# ESP8266 register map
File version: 1.0
CPU: Xtensa LX106 1, little endian, no MPU, no FPU, 3 interrupt priority bits
Registers are 32-bit, read-write, reset 0x0 unless marked. A register's access mark holds for its fields unless they carry their own. Offsets are from the block's base; [hi:lo] are bit positions; {n}, {i} and the like mark numbered series; 'fields as' and 'values as' point back to an identical list.

## I2S
Base 0x60000E00
0x00 I2STXFIFO
0x04 I2SRXFIFO
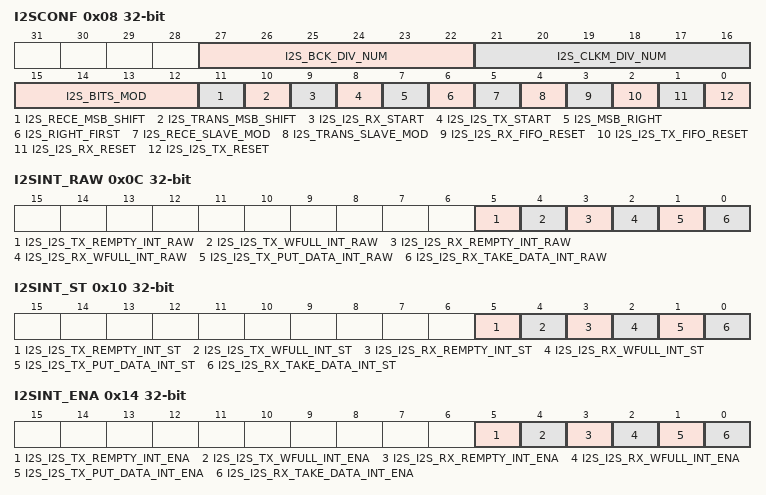
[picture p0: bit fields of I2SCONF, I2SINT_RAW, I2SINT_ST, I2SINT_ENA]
0x08 I2SCONF
  [27:22] I2S_BCK_DIV_NUM, [21:16] I2S_CLKM_DIV_NUM, [15:12] I2S_BITS_MOD, [11] I2S_RECE_MSB_SHIFT, [10] I2S_TRANS_MSB_SHIFT, [9] I2S_I2S_RX_START, [8] I2S_I2S_TX_START, [7] I2S_MSB_RIGHT, [6] I2S_RIGHT_FIRST, [5] I2S_RECE_SLAVE_MOD, [4] I2S_TRANS_SLAVE_MOD, [3] I2S_I2S_RX_FIFO_RESET, [2] I2S_I2S_TX_FIFO_RESET, [1] I2S_I2S_RX_RESET, [0] I2S_I2S_TX_RESET
0x0C I2SINT_RAW
  [5] I2S_I2S_TX_REMPTY_INT_RAW, [4] I2S_I2S_TX_WFULL_INT_RAW, [3] I2S_I2S_RX_REMPTY_INT_RAW, [2] I2S_I2S_RX_WFULL_INT_RAW, [1] I2S_I2S_TX_PUT_DATA_INT_RAW, [0] I2S_I2S_RX_TAKE_DATA_INT_RAW
0x10 I2SINT_ST
  [5] I2S_I2S_TX_REMPTY_INT_ST, [4] I2S_I2S_TX_WFULL_INT_ST, [3] I2S_I2S_RX_REMPTY_INT_ST, [2] I2S_I2S_RX_WFULL_INT_ST, [1] I2S_I2S_TX_PUT_DATA_INT_ST, [0] I2S_I2S_RX_TAKE_DATA_INT_ST
0x14 I2SINT_ENA
  [5] I2S_I2S_TX_REMPTY_INT_ENA, [4] I2S_I2S_TX_WFULL_INT_ENA, [3] I2S_I2S_RX_REMPTY_INT_ENA, [2] I2S_I2S_RX_WFULL_INT_ENA, [1] I2S_I2S_TX_PUT_DATA_INT_ENA, [0] I2S_I2S_RX_TAKE_DATA_INT_ENA
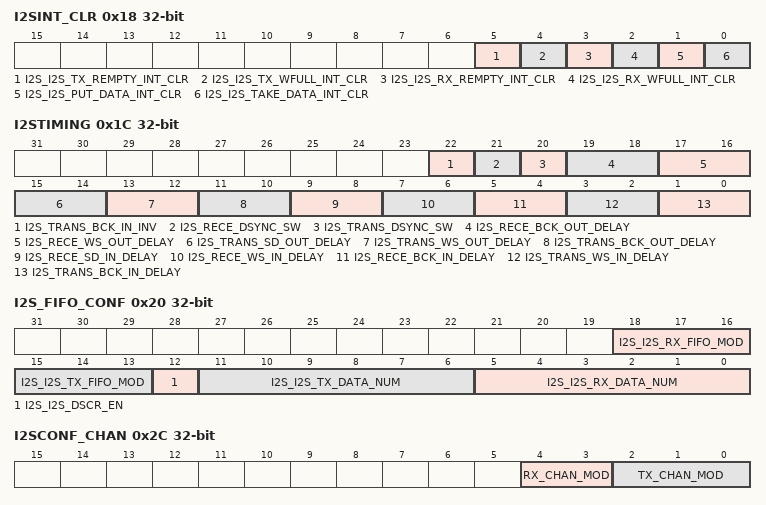
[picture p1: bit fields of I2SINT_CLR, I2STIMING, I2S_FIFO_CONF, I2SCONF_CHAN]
0x18 I2SINT_CLR
  [5] I2S_I2S_TX_REMPTY_INT_CLR, [4] I2S_I2S_TX_WFULL_INT_CLR, [3] I2S_I2S_RX_REMPTY_INT_CLR, [2] I2S_I2S_RX_WFULL_INT_CLR, [1] I2S_I2S_PUT_DATA_INT_CLR, [0] I2S_I2S_TAKE_DATA_INT_CLR
0x1C I2STIMING
  [22] I2S_TRANS_BCK_IN_INV, [21] I2S_RECE_DSYNC_SW, [20] I2S_TRANS_DSYNC_SW, [19:18] I2S_RECE_BCK_OUT_DELAY, [17:16] I2S_RECE_WS_OUT_DELAY, [15:14] I2S_TRANS_SD_OUT_DELAY, [13:12] I2S_TRANS_WS_OUT_DELAY, [11:10] I2S_TRANS_BCK_OUT_DELAY, [9:8] I2S_RECE_SD_IN_DELAY, [7:6] I2S_RECE_WS_IN_DELAY, [5:4] I2S_RECE_BCK_IN_DELAY, [3:2] I2S_TRANS_WS_IN_DELAY, [1:0] I2S_TRANS_BCK_IN_DELAY
0x20 I2S_FIFO_CONF
  [18:16] I2S_I2S_RX_FIFO_MOD, [15:13] I2S_I2S_TX_FIFO_MOD, [12] I2S_I2S_DSCR_EN, [11:6] I2S_I2S_TX_DATA_NUM, [5:0] I2S_I2S_RX_DATA_NUM
0x24 I2SRXEOF_NUM
  [31:0] I2S_I2S_RX_EOF_NUM
0x28 I2SCONF_SIGLE_DATA
  [31:0] I2S_I2S_SIGLE_DATA
0x2C I2SCONF_CHAN — I2S channel mode
  [4:3] RX_CHAN_MOD — Receive channel mode
  [2:0] TX_CHAN_MOD — Transmit channel mode

## IO_MUX
Base 0x60000800
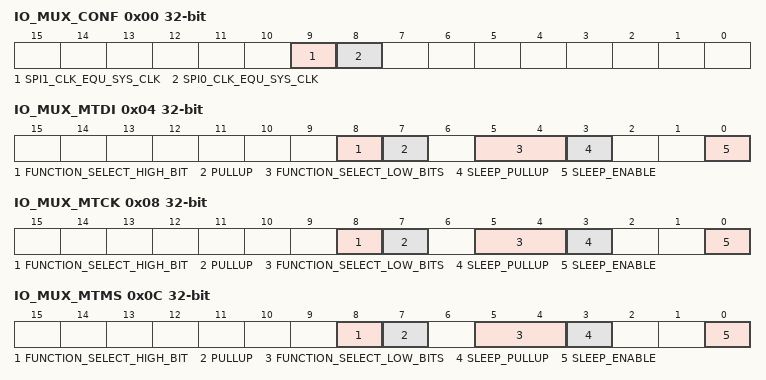
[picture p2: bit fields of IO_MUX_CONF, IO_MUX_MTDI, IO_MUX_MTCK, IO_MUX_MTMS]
0x00 IO_MUX_CONF
  [9] SPI1_CLK_EQU_SYS_CLK, [8] SPI0_CLK_EQU_SYS_CLK
0x04 IO_MUX_MTDI access not given
  [8] FUNCTION_SELECT_HIGH_BIT — configures IO_MUX function, upper bit
  [7] PULLUP — configures pull up
  [5:4] FUNCTION_SELECT_LOW_BITS — configures IO_MUX function, bottom 2 bits
  [3] SLEEP_PULLUP — configures pull up during sleep mode
  [0] SLEEP_ENABLE — configures output enable during sleep mode
0x08 IO_MUX_MTCK access not given
  fields as IO_MUX_MTDI
0x0C IO_MUX_MTMS access not given
  fields as IO_MUX_MTDI
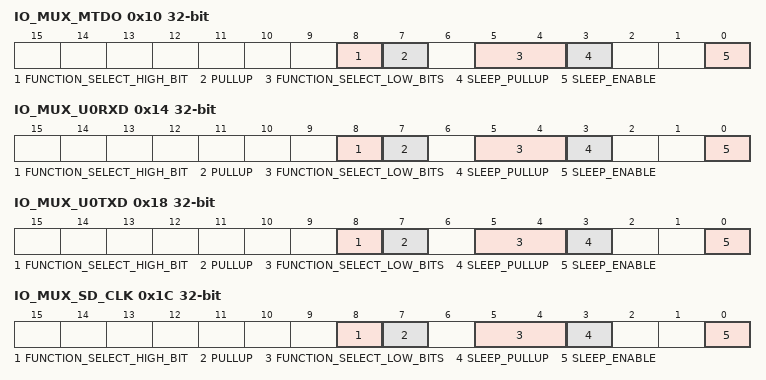
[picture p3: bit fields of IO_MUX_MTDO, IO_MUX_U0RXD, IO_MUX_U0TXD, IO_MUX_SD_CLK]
0x10 IO_MUX_MTDO access not given
  fields as IO_MUX_MTDI
0x14 IO_MUX_U0RXD access not given
  fields as IO_MUX_MTDI
0x18 IO_MUX_U0TXD access not given
  fields as IO_MUX_MTDI
0x1C IO_MUX_SD_CLK access not given
  fields as IO_MUX_MTDI
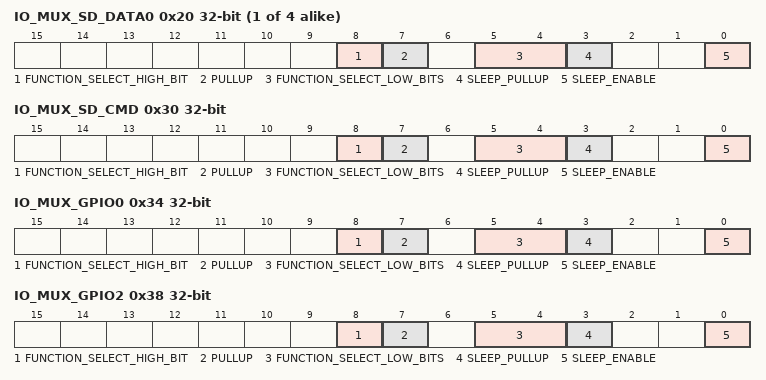
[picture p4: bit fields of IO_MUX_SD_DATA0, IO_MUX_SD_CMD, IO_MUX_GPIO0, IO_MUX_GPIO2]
{0x20+4i} IO_MUX_SD_DATA{i} access not given (i=0..3)
  fields as IO_MUX_MTDI
0x30 IO_MUX_SD_CMD access not given
  fields as IO_MUX_MTDI
0x34 IO_MUX_GPIO0 access not given
  fields as IO_MUX_MTDI
0x38 IO_MUX_GPIO2 access not given
  fields as IO_MUX_MTDI
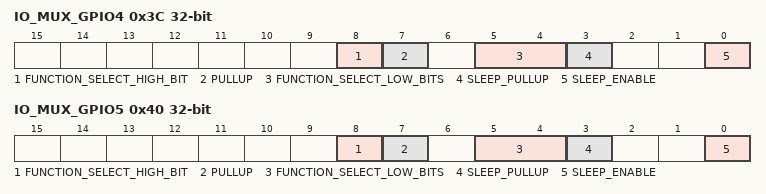
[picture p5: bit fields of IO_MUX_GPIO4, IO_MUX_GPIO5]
0x3C IO_MUX_GPIO4 access not given
  fields as IO_MUX_MTDI
0x40 IO_MUX_GPIO5 access not given
  fields as IO_MUX_MTDI

## RTC
Base 0x60000700
0x04 RTC_SLP_VAL — Target value of the RTC counter for waking from light or deep sleep
0x14 RTC_STATE1
0x18 RTC_STATE2
0x1C RTC_SLP_CNT_VAL — Current value of the RTC counter
0x30 RTC_STORE0
{0x30+4i} RTC_STORE{i} (i=1..3) — Scratch register kept across a watchdog reset (RTC_SCRATCH{i})
0x68 RTC_GPIO_OUT
0x74 RTC_GPIO_ENABLE
0x8C RTC_GPIO_IN_DATA
0x90 RTC_GPIO_CONF
0xA0 PAD_XPD_DCDC_CONF

## SLC
Base 0x60000B00
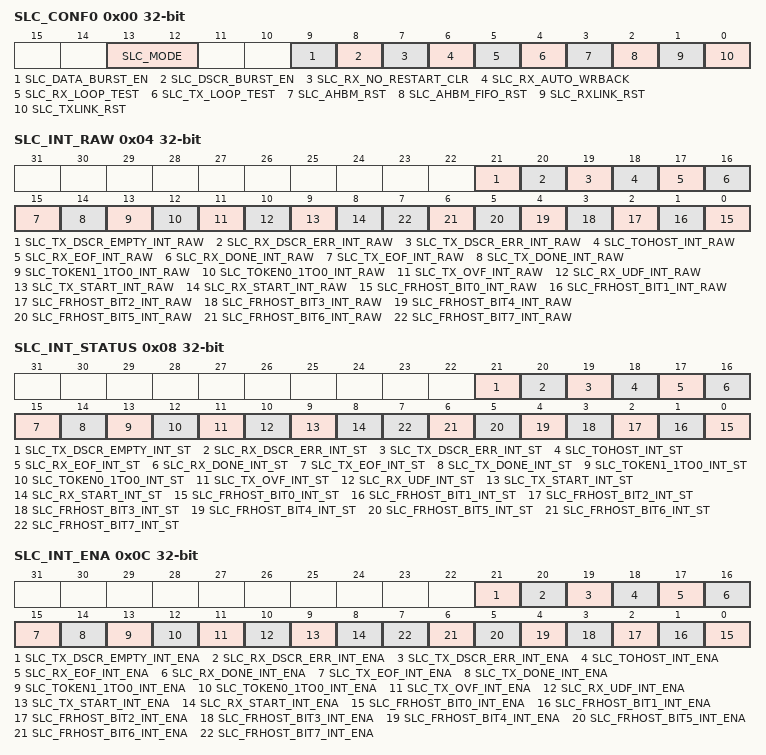
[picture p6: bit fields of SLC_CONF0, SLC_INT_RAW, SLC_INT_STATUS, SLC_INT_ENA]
0x00 SLC_CONF0
  [13:12] SLC_MODE, [9] SLC_DATA_BURST_EN, [8] SLC_DSCR_BURST_EN, [7] SLC_RX_NO_RESTART_CLR, [6] SLC_RX_AUTO_WRBACK, [5] SLC_RX_LOOP_TEST, [4] SLC_TX_LOOP_TEST, [3] SLC_AHBM_RST, [2] SLC_AHBM_FIFO_RST, [1] SLC_RXLINK_RST, [0] SLC_TXLINK_RST
0x04 SLC_INT_RAW
  [21] SLC_TX_DSCR_EMPTY_INT_RAW, [20] SLC_RX_DSCR_ERR_INT_RAW, [19] SLC_TX_DSCR_ERR_INT_RAW, [18] SLC_TOHOST_INT_RAW, [17] SLC_RX_EOF_INT_RAW, [16] SLC_RX_DONE_INT_RAW, [15] SLC_TX_EOF_INT_RAW, [14] SLC_TX_DONE_INT_RAW, [13] SLC_TOKEN1_1TO0_INT_RAW, [12] SLC_TOKEN0_1TO0_INT_RAW, [11] SLC_TX_OVF_INT_RAW, [10] SLC_RX_UDF_INT_RAW, [9] SLC_TX_START_INT_RAW, [8] SLC_RX_START_INT_RAW, [n] SLC_FRHOST_BIT{n}_INT_RAW (n=0..7)
0x08 SLC_INT_STATUS
  [21] SLC_TX_DSCR_EMPTY_INT_ST, [20] SLC_RX_DSCR_ERR_INT_ST, [19] SLC_TX_DSCR_ERR_INT_ST, [18] SLC_TOHOST_INT_ST, [17] SLC_RX_EOF_INT_ST, [16] SLC_RX_DONE_INT_ST, [15] SLC_TX_EOF_INT_ST, [14] SLC_TX_DONE_INT_ST, [13] SLC_TOKEN1_1TO0_INT_ST, [12] SLC_TOKEN0_1TO0_INT_ST, [11] SLC_TX_OVF_INT_ST, [10] SLC_RX_UDF_INT_ST, [9] SLC_TX_START_INT_ST, [8] SLC_RX_START_INT_ST, [n] SLC_FRHOST_BIT{n}_INT_ST (n=0..7)
0x0C SLC_INT_ENA
  [21] SLC_TX_DSCR_EMPTY_INT_ENA, [20] SLC_RX_DSCR_ERR_INT_ENA, [19] SLC_TX_DSCR_ERR_INT_ENA, [18] SLC_TOHOST_INT_ENA, [17] SLC_RX_EOF_INT_ENA, [16] SLC_RX_DONE_INT_ENA, [15] SLC_TX_EOF_INT_ENA, [14] SLC_TX_DONE_INT_ENA, [13] SLC_TOKEN1_1TO0_INT_ENA, [12] SLC_TOKEN0_1TO0_INT_ENA, [11] SLC_TX_OVF_INT_ENA, [10] SLC_RX_UDF_INT_ENA, [9] SLC_TX_START_INT_ENA, [8] SLC_RX_START_INT_ENA, [n] SLC_FRHOST_BIT{n}_INT_ENA (n=0..7)
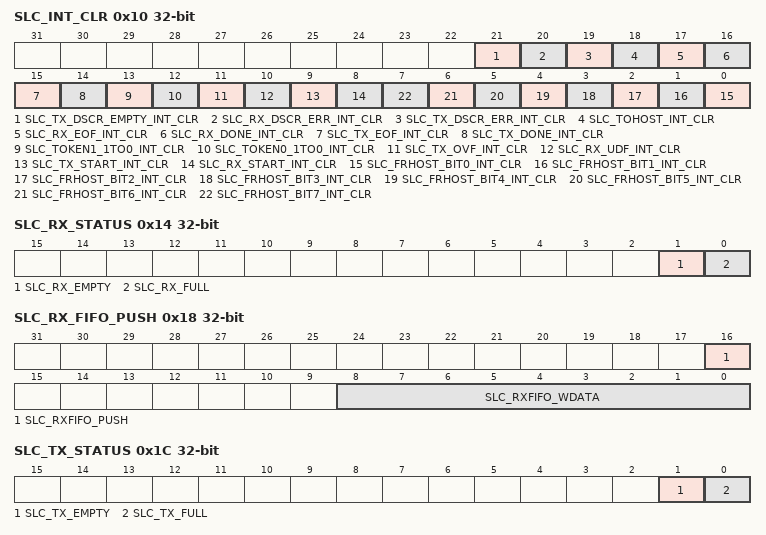
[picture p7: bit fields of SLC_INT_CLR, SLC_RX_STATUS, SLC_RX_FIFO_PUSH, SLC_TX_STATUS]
0x10 SLC_INT_CLR
  [21] SLC_TX_DSCR_EMPTY_INT_CLR, [20] SLC_RX_DSCR_ERR_INT_CLR, [19] SLC_TX_DSCR_ERR_INT_CLR, [18] SLC_TOHOST_INT_CLR, [17] SLC_RX_EOF_INT_CLR, [16] SLC_RX_DONE_INT_CLR, [15] SLC_TX_EOF_INT_CLR, [14] SLC_TX_DONE_INT_CLR, [13] SLC_TOKEN1_1TO0_INT_CLR, [12] SLC_TOKEN0_1TO0_INT_CLR, [11] SLC_TX_OVF_INT_CLR, [10] SLC_RX_UDF_INT_CLR, [9] SLC_TX_START_INT_CLR, [8] SLC_RX_START_INT_CLR, [n] SLC_FRHOST_BIT{n}_INT_CLR (n=0..7)
0x14 SLC_RX_STATUS
  [1] SLC_RX_EMPTY, [0] SLC_RX_FULL
0x18 SLC_RX_FIFO_PUSH
  [16] SLC_RXFIFO_PUSH, [8:0] SLC_RXFIFO_WDATA
0x1C SLC_TX_STATUS
  [1] SLC_TX_EMPTY, [0] SLC_TX_FULL
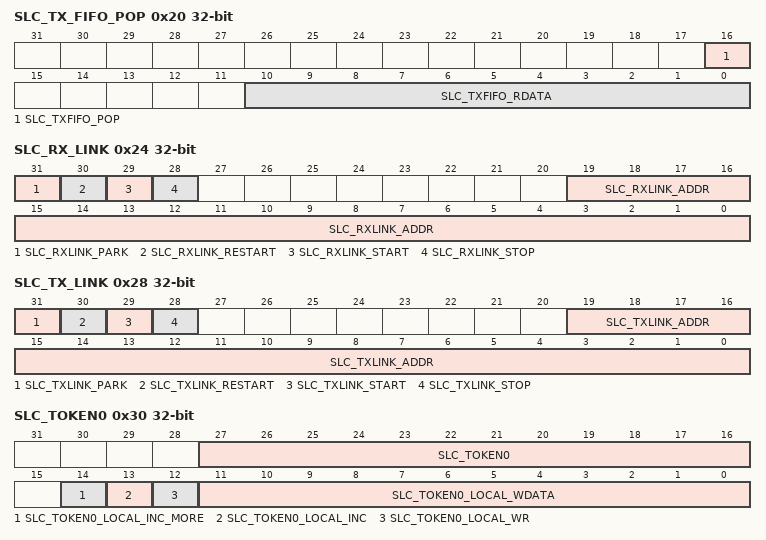
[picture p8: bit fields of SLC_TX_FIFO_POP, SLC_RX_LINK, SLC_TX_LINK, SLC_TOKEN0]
0x20 SLC_TX_FIFO_POP
  [16] SLC_TXFIFO_POP, [10:0] SLC_TXFIFO_RDATA
0x24 SLC_RX_LINK
  [31] SLC_RXLINK_PARK, [30] SLC_RXLINK_RESTART, [29] SLC_RXLINK_START, [28] SLC_RXLINK_STOP, [19:0] SLC_RXLINK_ADDR
0x28 SLC_TX_LINK
  [31] SLC_TXLINK_PARK, [30] SLC_TXLINK_RESTART, [29] SLC_TXLINK_START, [28] SLC_TXLINK_STOP, [19:0] SLC_TXLINK_ADDR
0x2C SLC_INTVEC_TOHOST
  [7:0] SLC_TOHOST_INTVEC
0x30 SLC_TOKEN0
  [27:16] SLC_TOKEN0, [14] SLC_TOKEN0_LOCAL_INC_MORE, [13] SLC_TOKEN0_LOCAL_INC, [12] SLC_TOKEN0_LOCAL_WR, [11:0] SLC_TOKEN0_LOCAL_WDATA
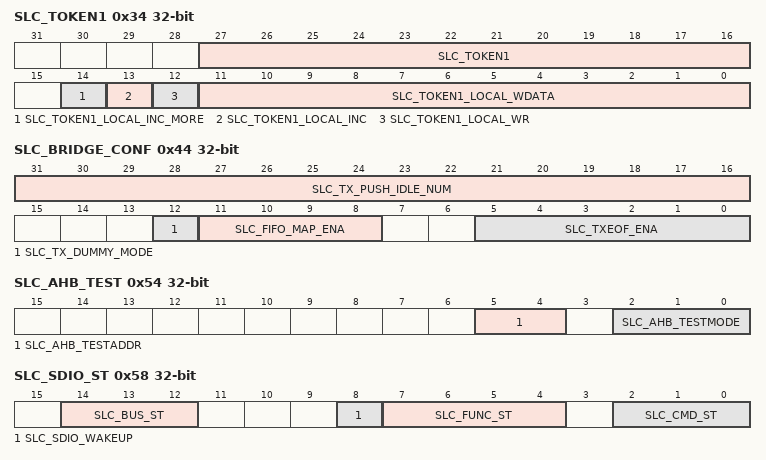
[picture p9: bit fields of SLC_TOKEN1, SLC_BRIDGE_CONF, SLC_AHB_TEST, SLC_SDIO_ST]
0x34 SLC_TOKEN1
  [27:16] SLC_TOKEN1, [14] SLC_TOKEN1_LOCAL_INC_MORE, [13] SLC_TOKEN1_LOCAL_INC, [12] SLC_TOKEN1_LOCAL_WR, [11:0] SLC_TOKEN1_LOCAL_WDATA
0x38 SLC_CONF1
0x3C SLC_STATE0
0x40 SLC_STATE1
0x44 SLC_BRIDGE_CONF
  [31:16] SLC_TX_PUSH_IDLE_NUM, [12] SLC_TX_DUMMY_MODE, [11:8] SLC_FIFO_MAP_ENA, [5:0] SLC_TXEOF_ENA
0x48 SLC_RX_EOF_DES_ADDR
0x4C SLC_TX_EOF_DES_ADDR
0x50 SLC_RX_EOF_BFR_DES_ADDR
0x54 SLC_AHB_TEST
  [5:4] SLC_AHB_TESTADDR, [2:0] SLC_AHB_TESTMODE
0x58 SLC_SDIO_ST
  [14:12] SLC_BUS_ST, [8] SLC_SDIO_WAKEUP, [7:4] SLC_FUNC_ST, [2:0] SLC_CMD_ST
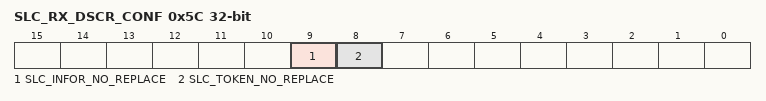
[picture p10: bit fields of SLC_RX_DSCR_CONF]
0x5C SLC_RX_DSCR_CONF
  [9] SLC_INFOR_NO_REPLACE, [8] SLC_TOKEN_NO_REPLACE
0x60 SLC_TXLINK_DSCR
0x64 SLC_TXLINK_DSCR_BF0
0x68 SLC_TXLINK_DSCR_BF1
0x6C SLC_RXLINK_DSCR
0x70 SLC_RXLINK_DSCR_BF0
0x74 SLC_RXLINK_DSCR_BF1
0x78 SLC_DATE
0x7C SLC_ID

## I2C_ANA — Internal I2C master of the analog blocks (PLL)
Base 0x60000D00
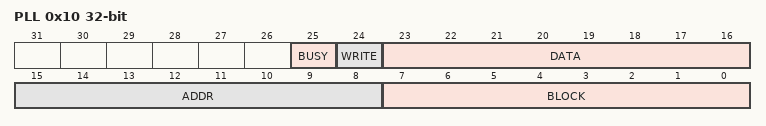
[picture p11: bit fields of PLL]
0x10 PLL — PLL I2C Register
  [25] BUSY — Ready
  [24] WRITE
  [23:16] DATA
  [15:8] ADDR — Address
  [7:0] BLOCK

## TIMER
Base 0x60000600
0x00 FRC1_LOAD — the load value into the counter
  [22:0] frc1_load_value
0x04 FRC1_COUNT ro — the current value of the counter. It is a decreasingcounter.
  [22:0] frc1_count
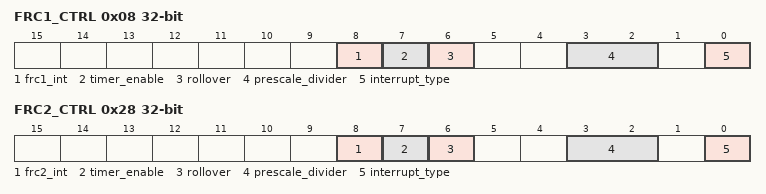
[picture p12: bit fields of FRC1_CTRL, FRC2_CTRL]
0x08 FRC1_CTRL access per field
  [8] frc1_int ro — the status of the interrupt, when the count isdereased to zero
  [7] timer_enable rw — Enable or disable the timer
  [6] rollover rw — Automatically reload when the counter hits zero
  [3:2] prescale_divider rw — Pre-scale divider for the timer
    0=devided_by_1 (divided by 1); 1=devided_by_16 (divided by 16); 2=devided_by_256 (divided by 256)
  [0] interrupt_type rw — Configure the interrupt type
    0=edge; 1=level
0x0C FRC1_INT
  [0] frc1_int_clr_mask — write to clear the status of the interrupt, if theinterrupt type is "level"
0x20 FRC2_LOAD — the load value into the counter
  [31:0] frc2_load_value
0x24 FRC2_COUNT ro — the current value of the counter. It is a increasingcounter.
0x28 FRC2_CTRL access per field
  [8] frc2_int ro — the status of the interrupt, when the count is equal tothe alarm value
  [7] timer_enable rw — Enable or disable the timer
  [6] rollover rw — Automatically reload when the counter hits zero
  [3:2] prescale_divider rw — Pre-scale divider for the timer
    values as FRC1_CTRL.prescale_divider
  [0] interrupt_type rw — Configure the interrupt type
    0=edge; 1=level
0x2C FRC2_INT
  [0] frc2_int_clr_mask — write to clear the status of the interrupt, if theinterrupt type is "level"
0x30 FRC2_ALARM — the alarm value for the counter

## WDT
Base 0x60000900
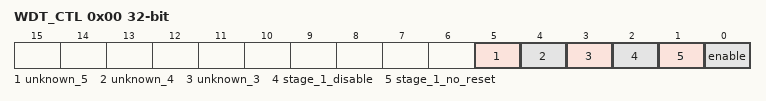
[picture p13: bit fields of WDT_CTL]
0x00 WDT_CTL access not given
  [5] unknown_5
  [4] unknown_4
  [3] unknown_3
  [2] stage_1_disable — Set to 1 to disable the stage 1 of the watchdog timer
  [1] stage_1_no_reset — When set to 1, and running in two-stage mode, it turns the watchdog into a single shot timer that doesn't reset the device.
  [0] enable — Enable the watchdog timer.
0x04 WDT_OP — Reload value for stage 0
0x08 WDT_OP_ND — Reload value for stage 1
0x0C count — Watchdog clock cycle count
0x10 stage — The current watchdog stage
0x14 WDT_RST — Watchdog reset
0x18 reset_stage — Watchdog stage reset
